# iND83216 register map
Vendor: Indiemicro; Series: RealplumTiny; File version: 1.00
CPU: CM0 r0p1, selectable endian, no MPU, no FPU, 4 interrupt priority bits
Registers are 32-bit, read-write, no defined reset value unless marked. A register's access mark holds for its fields unless they carry their own. Offsets are from the block's base; [hi:lo] are bit positions; {n}, {i} and the like mark numbered series.

## GPIO — GPIO bit control and configuration
Base 0x50004400; register names take the prefix GPIO_
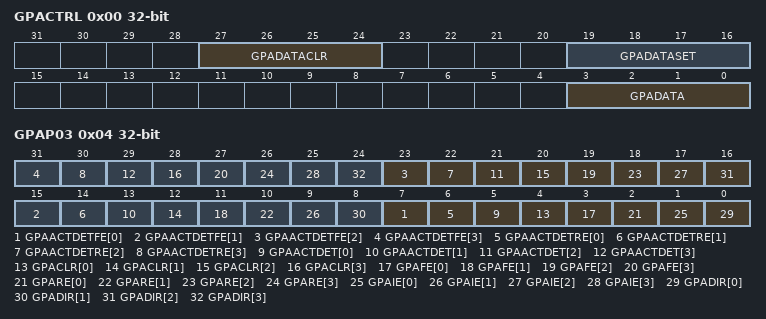
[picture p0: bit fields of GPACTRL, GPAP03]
0x00 GPACTRL — GPIO Port A Control Registers
  [27:24] GPADATACLR wo — Write-only register. Write 1 to clr the corresponding GPIO output data. Write 0 has no effects.
  [19:16] GPADATASET wo — Write-only register. Write 1 to set the corresponding GPIO output data. Write 0 has no effects.
  [3:0] GPADATA — Port A data. Read feedbacks the status of PORTs. Write to control the GPIO's output data.
0x04 GPAP03 — GPIO Port A Pin 0-3 Control
  [8n+7] GPAACTDETFE[{n}] ro (n=0..3) — PIN {n} activity fall status.
  [8n+6] GPAACTDETRE[{n}] ro (n=0..3) — PIN {n} activity rise status.
  [8n+5] GPAACTDET[{n}] ro (n=0..3) — Pin {n} activity interrupt.
  [8n+4] GPACLR[{n}] wo (n=0..3) — Pin {n} interrupt clear. Autoclear: includes a synchronous reset signal which clears the register on the cycle following write.
  [8n+3] GPAFE[{n}] (n=0..3) — Pin {n} falling edge enable.
  [8n+2] GPARE[{n}] (n=0..3) — Pin {n} rising edge enable.
  [8n+1] GPAIE[{n}] (n=0..3) — Pin {n} interrupt mask.
  [8n] GPADIR[{n}] (n=0..3) — Pin {n} output enable.
0x08 GPENA — GPIO Port Enables
  [0] GPAENA — GPIO Port A Clock enable.

## PWM — Control (and status) registers for the pulse width modulation waveform generator.
Base 0x50010000; register names take the prefix PWM_
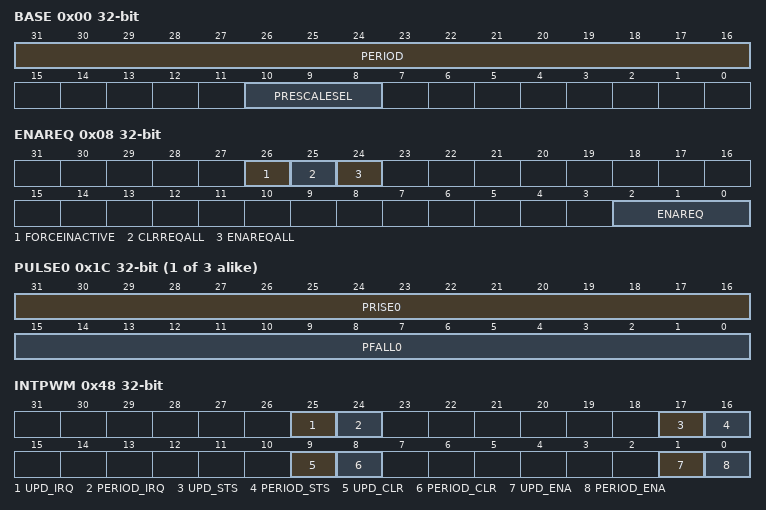
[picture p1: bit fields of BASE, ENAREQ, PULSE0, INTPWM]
0x00 BASE — Base functions
  [31:16] PERIOD — Period. Specifies the period of the output waveform in terms of a number of prescaler output cycles.
  [10:8] PRESCALESEL — Prescaler select. Defines the ratio between the system clock and the clock used for the waveform generator.0x0: Divide by 10x1: Divide by 20x2: Divide by 40x3: Divide by 80x4: Divide by 160x5: Divide by 640x6: Divide by 2560x7: Divide by 1024
0x04 PWMCNT — PWM Count Value
  [15:0] PWMCNT — PWM counter value to give a sense about the current period
0x08 ENAREQ — Enable request
  [26] FORCEINACTIVE — Set to force PWM signals return to initial value immediately.
  [25] CLRREQALL wo — Write 1 to clear all ENA_REQ bits; Write 0 has no effects.
  [24] ENAREQALL wo — Write 1 to enable all ENA_REQ bits; Write 0 has no effects.
  [2:0] ENAREQ — Set to enable the waveform generator.
0x0C ENASTS — Enable status
  [2:0] ENASTS ro — Status of enable in the waveform generator.
0x10 INIT — Intial State of Outputs
  [2:0] INIT — Set to initialise the output waveform.
0x14 INV — Invert
  [2:0] INVERT — Set to invert the output waveform.
0x18 UPDATE
  [0] UPDATE — Set to trigger consumption of new PULSE parameters (invert,prescale_sel,period,pulse start & stop). The flag is automatically cleared by the hardware when the settings are consumed, so reading a high value indicates that an update is still pending.
{0x1C+4i} PULSE{i} (i=0..2) — PWM{i} pulse setup
  [31:16] PRISE{i} — Pulse Rise. Specifies the pulse rise of the output waveform in terms of a number of prescaler output cycles. However, if INVERT is set it determines the pulse fall timing.
  [15:0] PFALL{i} — Pulse Fall. Specifies the pulse fall of the output waveform in terms of a number of prescaler output cycles. However, if INVERT is set it determines the pulse rise timing.
0x28 INTPOSEDGENA — PWM posedge interrupt enable
  [2:0] INTPOSEDGENA — Interrupt enable. bit[2:0]: posedge interrupt enable.
0x2C INTNEGEDGENA — PWM negedge interrupt enable
  [2:0] INTNEGEDGENA — Interrupt enable. bit[2:0]: negedge interrupt enable.
0x30 INTPOSEDGCLR — PWM posedge interrupt control
  [2:0] INTPOSEDGCLR wo — Interrupt clear. bit[2:0] : posedge interrupt clear.
0x34 INTNEGEDGCLR — PWM negedge interrupt control
  [2:0] INTNEGEDGCLR wo — Interrupt clear. bit[2:0] : negedge interrupt clear.
0x38 INTPOSEDGSTS — PWM posedge interrupt status
  [2:0] INTPOSEDGSTS ro — Interrupt status. bit[2:0] : posedge interrupt status.
0x3C INTNEGEDGSTS — PWM negedge interrupt status
  [2:0] INTNEGEDGSTS ro — Interrupt status. bit[2:0] : negedge interrupt status.
0x40 INTPOSEDGIRQ — PWM posedge interrupt active
  [2:0] INTPOSEDGIRQ ro — Interrupt active. bit[2:0] : posedge interrupt active.
0x44 INTNEGEDGIRQ — PWM negedge interrupt active
  [2:0] INTNEGEDGIRQ ro — Interrupt active. bit[2:0] : negedge interrupt active.
0x48 INTPWM — PWM interrupt control
  [25] UPD_IRQ ro — Updated Interrupt active.
  [24] PERIOD_IRQ ro — Period Interrupt active.
  [17] UPD_STS ro — Updated Interrupt status.
  [16] PERIOD_STS ro — Period Interrupt status.
  [9] UPD_CLR wo — Updated Interrupt clear.
  [8] PERIOD_CLR wo — Period Interrupt clear.
  [1] UPD_ENA — Updated Interrupt enable.
  [0] PERIOD_ENA — Period Interrupt enable.
